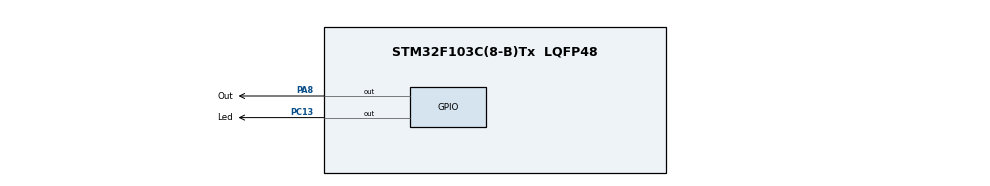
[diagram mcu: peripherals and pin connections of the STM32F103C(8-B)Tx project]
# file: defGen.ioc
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Mcu.Family=STM32F1
Mcu.Name=STM32F103C(8-B)Tx
Mcu.Package=LQFP48
NVIC.PriorityGroup=NVIC_PRIORITYGROUP_4
NVIC.TIM1_UP_IRQn=true\:0\:0\:false\:true\:true\:1\:true\:true
NVIC.TIM2_IRQn=true\:0\:0\:false\:true\:true\:2\:true\:true
PA13.Mode=Serial_Wire
PA13.Signal=SYS_JTMS-SWDIO
PA14.Mode=Serial_Wire
PA14.Signal=SYS_JTCK-SWCLK
PA8.GPIO_Label=Out
PA8.Signal=GPIO_Output
PC13-TAMPER-RTC.GPIO_Label=Led
PC13-TAMPER-RTC.Signal=GPIO_Output
PD0-OSC_IN.Mode=HSE-External-Oscillator
PD0-OSC_IN.Signal=RCC_OSC_IN
PD1-OSC_OUT.Mode=HSE-External-Oscillator
PD1-OSC_OUT.Signal=RCC_OSC_OUT
ProjectManager.HeapSize=0x200
ProjectManager.StackSize=0x400
ProjectManager.TargetToolchain=MDK-ARM V5.27
RCC.AHBFreq_Value=72000000
RCC.APB1CLKDivider=RCC_HCLK_DIV2
RCC.APB1Freq_Value=36000000
RCC.APB1TimFreq_Value=72000000
RCC.APB2Freq_Value=72000000
RCC.APB2TimFreq_Value=72000000
RCC.HCLKFreq_Value=72000000
RCC.PLLMUL=RCC_PLL_MUL9
RCC.PLLSourceVirtual=RCC_PLLSOURCE_HSE
RCC.SYSCLKFreq_VALUE=72000000
RCC.SYSCLKSource=RCC_SYSCLKSOURCE_PLLCLK
RCC.USBFreq_Value=72000000
TIM1.AutoReloadPreload=TIM_AUTORELOAD_PRELOAD_ENABLE
TIM1.Period=100
TIM1.Prescaler=71
TIM2.AutoReloadPreload=TIM_AUTORELOAD_PRELOAD_ENABLE
TIM2.Period=100
VP_TIM1_VS_ClockSourceINT.Mode=Internal
VP_TIM2_VS_ClockSourceINT.Mode=Internal
board=custom

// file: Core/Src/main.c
/* USER CODE BEGIN Header */
/**
  ******************************************************************************
  * @file           : main.c
  * @brief          : Main program body
  ******************************************************************************
  * @attention
  *
  * <h2><center>&copy; Copyright (c) 2021 STMicroelectronics.
  * All rights reserved.</center></h2>
  *
  * This software component is licensed by ST under BSD 3-Clause license,
  * the "License"; You may not use this file except in compliance with the
  * License. You may obtain a copy of the License at:
  *                        opensource.org/licenses/BSD-3-Clause
  *
  ******************************************************************************
  */
/* USER CODE END Header */
#include "main.h"
#define LENGHT 34
/* USER CODE BEGIN Includes */
volatile uint16_t new_state;
volatile _Bool processed;
volatile _Bool repeat;
/****************************/
volatile uint16_t countSend;
//uint16_t lenght;
/****************************/
uint32_t array[LENGHT][2] = {{0, 0},
{10, 1},
{10375, 0},
{10515, 1},
{74, 0},
{10814, 1},
{974, 0},
{11114, 1},
{15, 0},
{11524, 1},
{705, 0},
{91, 1},
{11906, 0},
{11916, 1},
{12107, 0},
{10, 1},
{12308, 0},
{20, 1},
{12509, 0},
{12595, 1},
{10, 0},
{20, 1},
{11, 0},
{98, 1},
{13112, 0},
{32, 1},
{313, 0},
{9, 1},
{514, 0},
{4, 1},
{13715, 0},
{14677, 1},
{60, 0},
{46000, 1}};/*array for saving values*/

static inline void Init(void){
	countSend = 0x00U;
	TIM1->ARR = 0x01U;
	new_state = 0x00U;
	TIM1->RCR = 0x00U;
	TIM1->PSC = 71U;
}
static inline void Increment(void){
	if(countSend < LENGHT - 1){
		++countSend;
	}
	else{
		countSend = 0x04U;
	}
}
static inline void getNext(void){
	volatile uint32_t temp = array[countSend][0];
	volatile uint16_t state = (uint32_t) array[countSend][1];
	if(temp < 0x03U){
		switch(temp){
			case 0x00U:
				Increment();
			break;
			case 0x01U:
				new_state = state;
				TIM1->ARR = 0x01;
				Increment();
				break;
			case 0x02U:
				new_state = state;
				TIM1->ARR = 0x01U;
				Increment();
			break;
		}
	}
	else if(temp >= 0x03U &&temp < 0xFFFFU){
		new_state = state;
		TIM1->ARR = temp -1U;
		Increment();
	}
	else{
		if(!repeat){
			repeat = true;
			TIM1->ARR = 0xFFFFU - 0x01U;
			TIM1->RCR = (temp/0xFFFFU)-0x01U;
			new_state = state;
		}
		else{
			repeat = false;
			TIM1->ARR = (temp%0xFFFFU)-0x01U;
			TIM1->RCR = 0x00U;
			new_state = state;
			Increment();
		}
	}
}

void SystemClock_Config(void);
static void MX_GPIO_Init(void);
static void MX_TIM1_Init(void);
static void MX_TIM2_Init(void);
static void MX_NVIC_Init(void);

int main(void)
{
  /* Reset of all peripherals, Initializes the Flash interface and the Systick. */

  LL_APB2_GRP1_EnableClock(LL_APB2_GRP1_PERIPH_AFIO);
  LL_APB1_GRP1_EnableClock(LL_APB1_GRP1_PERIPH_PWR);

  NVIC_SetPriorityGrouping(NVIC_PRIORITYGROUP_4);

  /* System interrupt init*/

  /** NOJTAG: JTAG-DP Disabled and SW-DP Enabled
  */
  LL_GPIO_AF_Remap_SWJ_NOJTAG();

  /* Configure the system clock */
  SystemClock_Config();

  /* USER CODE BEGIN SysInit */
  Init();
  /* USER CODE END SysInit */

  /* Initialize all configured peripherals */
  MX_GPIO_Init();
  MX_TIM1_Init();
  MX_TIM2_Init();

  /* Initialize interrupts */
  MX_NVIC_Init();
  /* USER CODE BEGIN 2 */
  LL_TIM_EnableCounter(TIM1);
  LL_TIM_EnableCounter(TIM2);
  /* USER CODE END 2 */

  /* Infinite loop */
  while (1)
  {
	  if(processed){
		  getNext();
		  processed = false;
	  }
	  //GPIOC->ODR^=(1U<<13);
  }
  /* USER CODE END 3 */
}

void SystemClock_Config(void)
{
  LL_FLASH_SetLatency(LL_FLASH_LATENCY_2);
  while(LL_FLASH_GetLatency()!= LL_FLASH_LATENCY_2)
  {
  }
  LL_RCC_HSE_Enable();

   /* Wait till HSE is ready */
  while(LL_RCC_HSE_IsReady() != 1)
  {

  }
  LL_RCC_PLL_ConfigDomain_SYS(LL_RCC_PLLSOURCE_HSE_DIV_1, LL_RCC_PLL_MUL_9);
  LL_RCC_PLL_Enable();

   /* Wait till PLL is ready */
  while(LL_RCC_PLL_IsReady() != 1)
  {

  }
  LL_RCC_SetAHBPrescaler(LL_RCC_SYSCLK_DIV_1);
  LL_RCC_SetAPB1Prescaler(LL_RCC_APB1_DIV_2);
  LL_RCC_SetAPB2Prescaler(LL_RCC_APB2_DIV_1);
  LL_RCC_SetSysClkSource(LL_RCC_SYS_CLKSOURCE_PLL);

   /* Wait till System clock is ready */
  while(LL_RCC_GetSysClkSource() != LL_RCC_SYS_CLKSOURCE_STATUS_PLL)
  {

  }
  LL_Init1msTick(72000000);
  LL_SetSystemCoreClock(72000000);
}

/**
  * @brief NVIC Configuration.
  * @retval None
  */
static void MX_NVIC_Init(void)
{
  /* TIM1_UP_IRQn interrupt configuration */
  NVIC_SetPriority(TIM1_UP_IRQn, NVIC_EncodePriority(NVIC_GetPriorityGrouping(),0, 0));
  NVIC_EnableIRQ(TIM1_UP_IRQn);
}

static void MX_TIM1_Init(void)
{

  LL_TIM_InitTypeDef TIM_InitStruct = {0};

  /* Peripheral clock enable */
  LL_APB2_GRP1_EnableClock(LL_APB2_GRP1_PERIPH_TIM1);

  TIM_InitStruct.Prescaler = 71;
  TIM_InitStruct.CounterMode = LL_TIM_COUNTERMODE_UP;
  TIM_InitStruct.Autoreload = 10;
  TIM_InitStruct.ClockDivision = LL_TIM_CLOCKDIVISION_DIV1;
  TIM_InitStruct.RepetitionCounter = 0;
  LL_TIM_Init(TIM1, &TIM_InitStruct);
  LL_TIM_EnableARRPreload(TIM1);
  LL_TIM_SetClockSource(TIM1, LL_TIM_CLOCKSOURCE_INTERNAL);
  LL_TIM_SetTriggerOutput(TIM1, LL_TIM_TRGO_RESET);
  LL_TIM_DisableMasterSlaveMode(TIM1);
  LL_TIM_EnableIT_UPDATE(TIM1);

}

static void MX_TIM2_Init(void)
{

  LL_TIM_InitTypeDef TIM_InitStruct = {0};

  /* Peripheral clock enable */
  LL_APB1_GRP1_EnableClock(LL_APB1_GRP1_PERIPH_TIM2);

  /* TIM2 interrupt Init */
  NVIC_SetPriority(TIM2_IRQn, NVIC_EncodePriority(NVIC_GetPriorityGrouping(),1, 0));
  NVIC_EnableIRQ(TIM2_IRQn);

  TIM_InitStruct.Prescaler = 7199;
  TIM_InitStruct.CounterMode = LL_TIM_COUNTERMODE_UP;
  TIM_InitStruct.Autoreload = 1666;
  TIM_InitStruct.ClockDivision = LL_TIM_CLOCKDIVISION_DIV1;
  LL_TIM_Init(TIM2, &TIM_InitStruct);
  LL_TIM_EnableARRPreload(TIM2);
  LL_TIM_SetClockSource(TIM2, LL_TIM_CLOCKSOURCE_INTERNAL);
  LL_TIM_SetTriggerOutput(TIM2, LL_TIM_TRGO_RESET);
  LL_TIM_DisableMasterSlaveMode(TIM2);
  LL_TIM_EnableIT_UPDATE(TIM2);

}

static void MX_GPIO_Init(void)
{
  LL_GPIO_InitTypeDef GPIO_InitStruct = {0};

  /* GPIO Ports Clock Enable */
  LL_APB2_GRP1_EnableClock(LL_APB2_GRP1_PERIPH_GPIOC);
  LL_APB2_GRP1_EnableClock(LL_APB2_GRP1_PERIPH_GPIOD);
  LL_APB2_GRP1_EnableClock(LL_APB2_GRP1_PERIPH_GPIOA);

  /**/
  LL_GPIO_ResetOutputPin(Led_GPIO_Port, Led_Pin);

  /**/
  LL_GPIO_SetOutputPin(Out_GPIO_Port, Out_Pin);

  /**/
  GPIO_InitStruct.Pin = Led_Pin;
  GPIO_InitStruct.Mode = LL_GPIO_MODE_OUTPUT;
  GPIO_InitStruct.Speed = LL_GPIO_SPEED_FREQ_LOW;
  GPIO_InitStruct.OutputType = LL_GPIO_OUTPUT_PUSHPULL;
  LL_GPIO_Init(Led_GPIO_Port, &GPIO_InitStruct);

  /**/
  GPIO_InitStruct.Pin = Out_Pin;
  GPIO_InitStruct.Mode = LL_GPIO_MODE_OUTPUT;
  GPIO_InitStruct.Speed = LL_GPIO_SPEED_FREQ_HIGH;
  GPIO_InitStruct.OutputType = LL_GPIO_OUTPUT_PUSHPULL;
  LL_GPIO_Init(Out_GPIO_Port, &GPIO_InitStruct);

}

void Error_Handler(void)
{
  __disable_irq();
  while (1)
  {
  }
}

/************************ (C) COPYRIGHT STMicroelectronics *****END OF FILE****/
